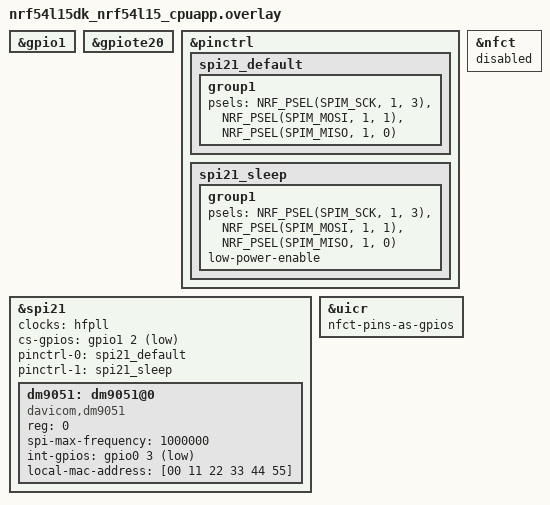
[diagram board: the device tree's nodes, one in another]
/*
 * Device Tree overlay for DM9051 SPI Ethernet Controller on nRF54L15DK
 * 
 * This overlay configures the DM9051 Ethernet controller connected via SPI21.
 * SPI21 supports cross-domain pins and can use GPIO1 pins.
 * 
 * Pin connections:
 * - SCK:  P1.12 - SPI Clock
 * - MOSI: P1.1 - SPI MOSI (Master Out Slave In)
 * - MISO: P1.0 - SPI MISO (Master In Slave Out)
 * - CS:   P1.2 - Chip Select (configured in cs-gpios)
 * - INT:  P0.3 - Interrupt pin
 * 
 * SPI Configuration:
 * - Interface: SPI21 (to avoid conflict with UART20 which uses the same hardware instance as SPI20)
 * - Max Frequency: 4MHz (conservative for stability)
 * - Can be increased to 8MHz if stable
 * 
 * Note: SPI20 and UART20 share the same hardware instance, so we use SPI21 instead.
 *       SPI00 is already used by the external flash memory.
 */

/* Ensure GPIO1 and its GPIOTE instance are enabled */
&gpio1 {
	status = "okay";
};

&gpiote20 {
	status = "okay";
};

&pinctrl {
	spi21_default: spi21_default {
		group1 {
			psels = <NRF_PSEL(SPIM_SCK, 1, 3)>,
				<NRF_PSEL(SPIM_MOSI, 1, 1)>,
				<NRF_PSEL(SPIM_MISO, 1, 0)>;
		};
	};

	spi21_sleep: spi21_sleep {
		group1 {
			psels = <NRF_PSEL(SPIM_SCK, 1, 3)>,
				<NRF_PSEL(SPIM_MOSI, 1, 1)>,
				<NRF_PSEL(SPIM_MISO, 1, 0)>;
			low-power-enable;
		};
	};
};

&spi21 {
	status = "okay";
	clocks = <&hfpll>;
	cs-gpios = <&gpio1 2 GPIO_ACTIVE_LOW>;  /* CS on P1.2 */
	pinctrl-0 = <&spi21_default>;
	pinctrl-1 = <&spi21_sleep>;
	pinctrl-names = "default", "sleep";
	
	dm9051: dm9051@0 {
		compatible = "davicom,dm9051";
		reg = <0>;
		spi-max-frequency = <1000000>;  /* 1MHz - minimum for debugging */
		int-gpios = <&gpio0 3 GPIO_ACTIVE_LOW>;
		
		/* Local MAC address */
		local-mac-address = [00 11 22 33 44 55];
	};
};

/* Disable NFCT to free up NFC pins for GPIO usage */
&nfct {
	status = "disabled";
};

/* Configure UICR to use NFCT pins as GPIOs */
&uicr {
	nfct-pins-as-gpios;
};
